# psoc6_03 register map
Vendor: Infineon Technologies; Series: PSOC6_03; File version: 1.0
CPU: CM4 r0p1, little endian, MPU, FPU, VTOR, 3 interrupt priority bits
Registers are 32-bit, read-write, reset 0x0 unless marked. A register's access mark holds for its fields unless they carry their own. Offsets are from the block's base; [hi:lo] are bit positions; {n}, {i} and the like mark numbered series; 'fields as' and 'values as' point back to an identical list.

## SRSS (part 2 of 2) — SRSS Core Registers
Base 0x40260000
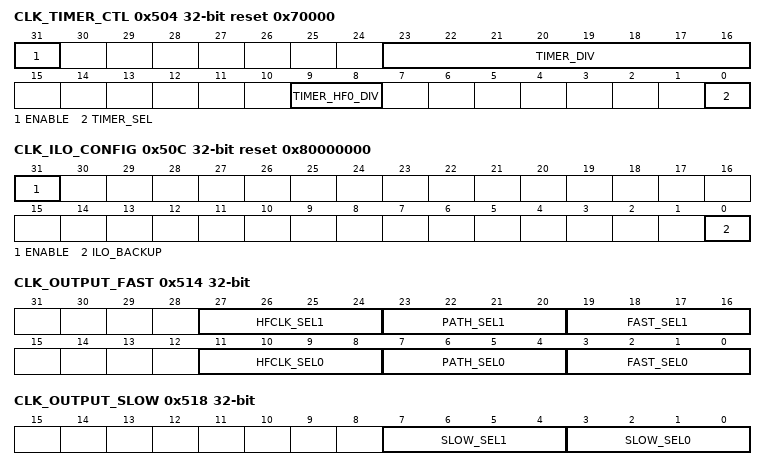
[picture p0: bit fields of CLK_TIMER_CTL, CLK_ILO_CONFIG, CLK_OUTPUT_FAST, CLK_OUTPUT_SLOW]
0x504 CLK_TIMER_CTL reset 0x70000 — Timer Clock Control Register
  [31] ENABLE — Enable for TIMERCLK. 0: TIMERCLK is off 1: TIMERCLK is enabled
  [23:16] TIMER_DIV — Divide selected timer clock source by (1+TIMER_DIV). The output of this divider is TIMERCLK Allows for integer divisions in the range [1, 256]. Do not change this setting while the timer is enabled.
  [9:8] TIMER_HF0_DIV — Predivider used when HF0_DIV is selected in TIMER_SEL. If HFCLK0 frequency is less than 100MHz and has approximately 50 percent duty cycle, then no division is required (NO_DIV). Otherwise, select a divide ratio of 2, 4, or 8 before selected HF0_DIV as the timer clock.
    0=NO_DIV (Transparent mode, feed through selected clock source w/o dividing or correcting duty cycle.); 1=DIV_BY_2 (Divide HFCLK0 by 2.); 2=DIV_BY_4 (Divide HFCLK0 by 4.); 3=DIV_BY_8 (Divide HFCLK0 by 8.)
  [0] TIMER_SEL — Select source for TIMERCLK. The output of this mux can be further divided using TIMER_DIV.
    0=IMO (IMO - Internal Main Oscillator); 1=HF0_DIV (Select the output of the predivider configured by TIMER_HF0_DIV.)
0x50C CLK_ILO_CONFIG reset 0x80000000 — ILO Configuration
  [31] ENABLE — Master enable for ILO. Writes to this field are ignored unless the WDT is unlocked using WDT_LOCK register. After enabling, it takes at most two cycles to reach the accuracy spec.
  [0] ILO_BACKUP — If backup domain is present on this product, this register indicates that ILO should stay enabled for use by backup domain during XRES, HIBERNATE mode, and through power-related resets like BOD on VDDD/VCCD. Writes to this field are ignored unless the WDT is unlocked using WDT_LOCK register. 0: ILO turns off at XRES/BOD event or HIBERNATE entry. 1: ILO remains on if backup domain is present and powered even for XRES/BOD or HIBERNATE entry.
0x510 CLK_IMO_CONFIG reset 0x80000000 — IMO Configuration
  [31] ENABLE — Master enable for IMO oscillator. This bit must be high at all times for all functions to work properly. Hardware will automatically disable the IMO during HIBERNATE and XRES. It will automatically disable during DEEPSLEEP if CLK_MFO_CONFIG.DPSLP_ENABLE==0.
0x514 CLK_OUTPUT_FAST — Fast Clock Output Select Register
  [27:24] HFCLK_SEL1 — Selects a HFCLK tree for use in fast clock output #1 logic
  [23:20] PATH_SEL1 — Selects a clock path to use in fast clock output #1 logic. 0: FLL output 1-15: PLL output on path1-path15 (if available)
  [19:16] FAST_SEL1 — Select signal for fast clock output #1
    0=NC (Disabled - output is 0. For power savings, clocks are blocked before entering any muxes, including PATH_SEL1 and HFCLK_SEL1.); 1=ECO (External Crystal Oscillator (ECO)); 2=EXTCLK (External clock input (EXTCLK)); 3=ALTHF (Alternate High-Frequency (ALTHF) clock input to SRSS); 4=TIMERCLK (Timer clock. It is grouped with the fast clocks because it may be a gated version of a fast clock, and therefore may have a short high pulse.); 5=PATH_SEL1 (Selects the clock path chosen by PATH_SEL1 field); 6=HFCLK_SEL1 (Selects the output of the HFCLK_SEL1 mux); 7=SLOW_SEL1 (Selects the output of CLK_OUTPUT_SLOW.SLOW_SEL1)
  [11:8] HFCLK_SEL0 — Selects a HFCLK tree for use in fast clock output #0
  [7:4] PATH_SEL0 — Selects a clock path to use in fast clock output #0 logic. 0: FLL output 1-15: PLL output on path1-path15 (if available)
  [3:0] FAST_SEL0 — Select signal for fast clock output #0
    0=NC (Disabled - output is 0. For power savings, clocks are blocked before entering any muxes, including PATH_SEL0 and HFCLK_SEL0.); 1=ECO (External Crystal Oscillator (ECO)); 2=EXTCLK (External clock input (EXTCLK)); 3=ALTHF (Alternate High-Frequency (ALTHF) clock input to SRSS); 4=TIMERCLK (Timer clock. It is grouped with the fast clocks because it may be a gated version of a fast clock, and therefore may have a short high pulse.); 5=PATH_SEL0 (Selects the clock path chosen by PATH_SEL0 field); 6=HFCLK_SEL0 (Selects the output of the HFCLK_SEL0 mux); 7=SLOW_SEL0 (Selects the output of CLK_OUTPUT_SLOW.SLOW_SEL0)
0x518 CLK_OUTPUT_SLOW — Slow Clock Output Select Register
  [7:4] SLOW_SEL1 — Select signal for slow clock output #1
    0=NC (Disabled - output is 0. For power savings, clocks are blocked before entering any muxes.); 1=ILO (Internal Low Speed Oscillator (ILO)); 2=WCO (Watch-Crystal Oscillator (WCO)); 3=BAK (Root of the Backup domain clock tree (BAK)); 4=ALTLF (Alternate low-frequency clock input to SRSS (ALTLF)); 5=LFCLK (Root of the low-speed clock tree (LFCLK)); 6=IMO (Internal Main Oscillator (IMO). This is grouped with the slow clocks so it can be observed during DEEPSLEEP entry/exit.); 7=SLPCTRL (Sleep Controller clock (SLPCTRL). This is grouped with the slow clocks so it can be observed during DEEPSLEEP entry/exit.); 8=PILO (Precision Internal Low Speed Oscillator (PILO))
  [3:0] SLOW_SEL0 — Select signal for slow clock output #0
    values as SLOW_SEL1
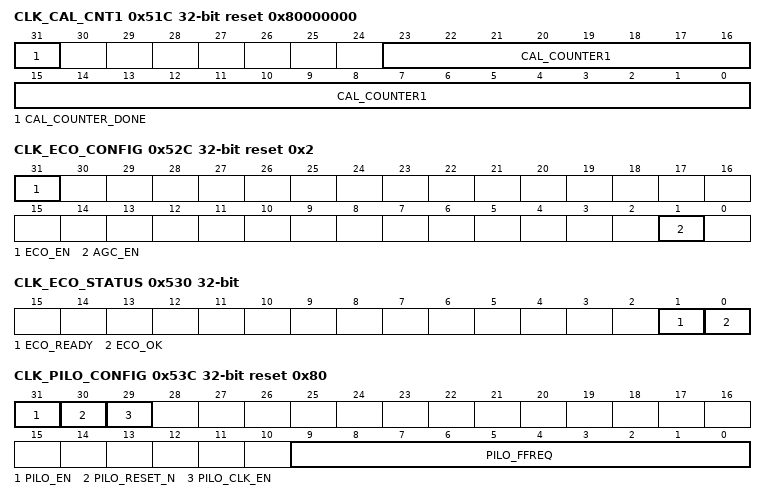
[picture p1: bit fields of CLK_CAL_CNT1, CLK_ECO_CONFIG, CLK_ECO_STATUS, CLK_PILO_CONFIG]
0x51C CLK_CAL_CNT1 reset 0x80000000 — Clock Calibration Counter 1
  [31] CAL_COUNTER_DONE ro — Status bit indicating that the internal counter #1 is finished counting and CLK_CAL_CNT2.COUNTER stopped counting up
  [23:0] CAL_COUNTER1 — Down-counter clocked on fast clock output #0 (see CLK_OUTPUT_FAST). This register always reads as zero. Counting starts internally when this register is written with a nonzero value. CAL_COUNTER_DONE goes immediately low to indicate that the counter has started and will be asserted when the counters are done. Do not write this field unless CAL_COUNTER_DONE==1. Both clocks must be running or the measurement will not complete. A stalled counter can be recovered by selecting valid clocks, waiting until the measurement completes, and discarding the first result.
0x520 CLK_CAL_CNT2 ro — Clock Calibration Counter 2
  [23:0] CAL_COUNTER2 — Up-counter clocked on fast clock output #1 (see CLK_OUTPUT_FAST). When CLK_CAL_CNT1.CAL_COUNTER_DONE==1, the counter is stopped and can be read by SW. Do not read this value unless CAL_COUNTER_DONE==1. The expected final value is related to the ratio of clock frequencies used for the two counters and the value loaded into counter 1: CLK_CAL_CNT2.COUNTER=(F_cnt2/F_cnt1)*(CLK_CAL_CNT1.COUNTER)
0x52C CLK_ECO_CONFIG reset 0x2 — ECO Configuration Register
  [31] ECO_EN — Master enable for ECO oscillator.
  [1] AGC_EN — Automatic Gain Control (AGC) enable. When set, the oscillation amplitude is controlled to the level selected by ECO_TRIM0.ATRIM. When low, the amplitude is not explicitly controlled and can be as high as the vddd supply. WARNING: use care when disabling AGC because driving a crystal beyond its rated limit can permanently damage the crystal.
0x530 CLK_ECO_STATUS ro — ECO Status Register
  [1] ECO_READY — Indicates the ECO internal oscillator circuit has had enough time to fully stabilize. This is the output of a counter since ECO was enabled, and it does not check the ECO output. It is recommended to also confirm ECO_OK==1.
  [0] ECO_OK — Indicates the ECO internal oscillator circuit has sufficient amplitude. It may not meet the PPM accuracy or duty cycle spec.
0x53C CLK_PILO_CONFIG reset 0x80 — Precision ILO Configuration Register
  [31] PILO_EN — Enable PILO. When enabling PILO, set PILO_EN=1, wait 1ms, then PILO_RESET_N=1 and PILO_CLK_EN=1. When disabling PILO, clear PILO_EN=0, PILO_RESET_N=0, and PLO_CLK_EN=0 in the same write cycle.
  [30] PILO_RESET_N — Reset the PILO. See PILO_EN field for required sequencing.
  [29] PILO_CLK_EN — Enable the PILO clock output. See PILO_EN field for required sequencing.
  [9:0] PILO_FFREQ — Fine frequency trim allowing +/-250ppm accuracy with periodic calibration. The nominal step size of the LSB is 8Hz.
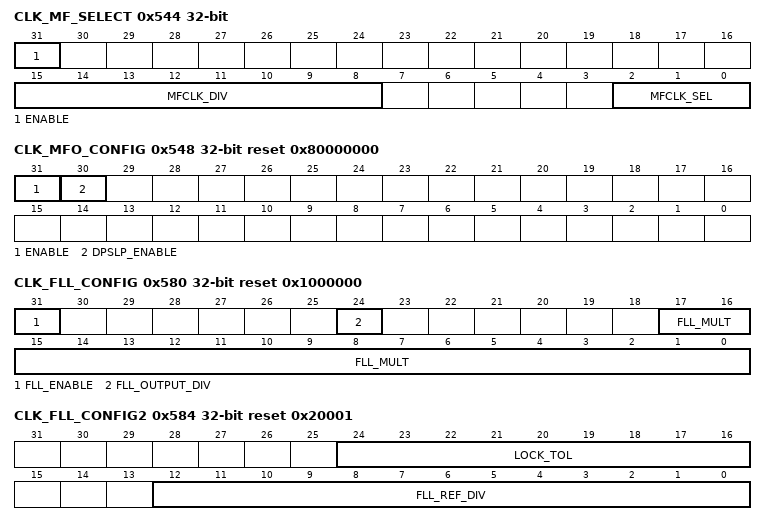
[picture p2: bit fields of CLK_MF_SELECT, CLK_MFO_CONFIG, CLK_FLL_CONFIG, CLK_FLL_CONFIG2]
0x544 CLK_MF_SELECT — Medium Frequency Clock Select Register
  [31] ENABLE — Enable for MFCLK (clk_mf).
  [15:8] MFCLK_DIV — Divide selected clock source by (1+MFCLK_DIV). The output of this divider is MFCLK (clk_mf). Allows for integer divisions in the range [1, 256]. Do not change this setting while ENABLE==1.
  [2:0] MFCLK_SEL — Select source for MFCLK (clk_mf). Note that not all products support all clock sources. Selecting a clock source that is not supported results in undefined behavior.
    0=MFO (MFO - medium frequency oscillator)
0x548 CLK_MFO_CONFIG reset 0x80000000 — MFO Configuration Register
  [31] ENABLE — Enable for MFO.
  [30] DPSLP_ENABLE — Enable for MFO during DEEPSLEEP. This bit is ignored when ENABLE==0. When ENABLE==1: 0: MFO is automatically disabled during DEEPSLEEP and enables upon wakeup; 1: MFO is kept enabled throughout DEEPSLEEP
0x580 CLK_FLL_CONFIG reset 0x1000000 — FLL Configuration Register
  [31] FLL_ENABLE — Master enable for FLL. The FLL requires firmware sequencing when enabling, disabling, and entering/exiting DEEPSLEEP. To enable the FLL, first enable the CCO by writing CLK_FLL_CONFIG4.CCO_ENABLE=1 and wait until CLK_FLL_STATUS.CCO_READY==1. Next, ensure the reference clock has stabilized and CLK_FLL_CONFIG3.BYPASS_SEL=FLL_REF. Next, write FLL_ENABLE=1 and wait until CLK_FLL_STATUS.LOCKED==1. Finally, write CLK_FLL_CONFIG3.BYPASS_SEL=FLL_OUT to switch to the FLL output. It takes seven reference clock cycles plus four FLL output cycles to switch to the FLL output. Do not disable the FLL before this time completes. To disable the FLL, write CLK_FLL_CONFIG3.BYPASS_SEL=FLL_REF and (optionally) read the same register to ensure the write completes. Then, wait at least seven FLL reference clock cycles before disabling it with FLL_ENABLE=0. Lastly, disable the CCO by writing CLK_FLL_CONFIG4.CCO_ENABLE=0. Before entering DEEPSLEEP, either disable the FLL using above sequence or use the following procedure to deselect/select it before/after DEEPSLEEP. Before entering DEEPSLEEP, write CLK_FLL_CONFIG3.BYPASS_SEL=FLL_REF to change the FLL to use its reference clock. After DEEPSLEEP wakeup, wait until CLK_FLL_STATUS.LOCKED==1 and then write CLK_FLL_CONFIG3.BYPASS_SEL=FLL_OUT to switch to the FLL output. 0: Block is powered off 1: Block is powered on
  [24] FLL_OUTPUT_DIV — Control bits for Output divider. Set the divide value before enabling the FLL, and do not change it while FLL is enabled. 0: no division 1: divide by 2
  [17:0] FLL_MULT — Multiplier to determine CCO frequency in multiples of the frequency of the selected reference clock (Fref). Ffll = (FLL_MULT) * (Fref / REFERENCE_DIV) / (OUTPUT_DIV+1)
0x584 CLK_FLL_CONFIG2 reset 0x20001 — FLL Configuration Register 2
  [24:16] LOCK_TOL — Lock tolerance sets the error threshold for when the FLL output is considered locked to the reference input. A high tolerance can be used to lock more quickly or to track a less accurate source. The tolerance should be set so that the FLL does not unlock under normal conditions. The tolerance is the allowed difference between the count value for the ideal formula and the measured value. 0: tolerate error of 1 count value 1: tolerate error of 2 count values ... 511: tolerate error of 512 count values
  [12:0] FLL_REF_DIV — Control bits for reference divider. Set the divide value before enabling the FLL, and do not change it while FLL is enabled. 0: illegal (undefined behavior) 1: divide by 1 ... 8191: divide by 8191
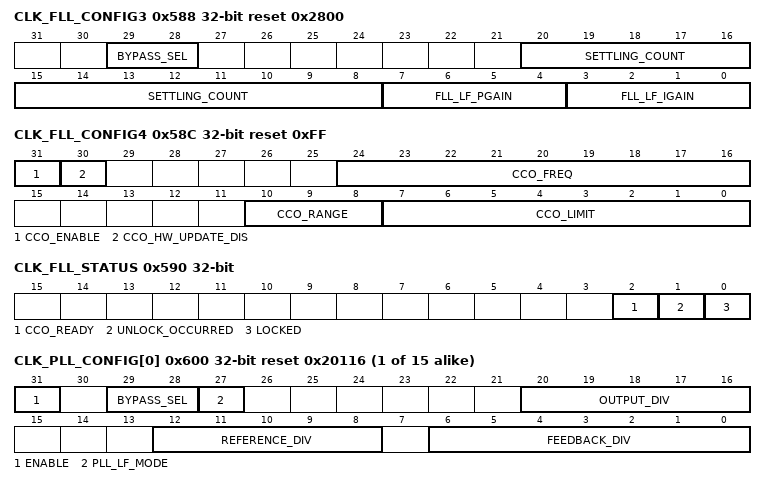
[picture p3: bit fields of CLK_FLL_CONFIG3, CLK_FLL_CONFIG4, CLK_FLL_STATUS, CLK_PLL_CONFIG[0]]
0x588 CLK_FLL_CONFIG3 reset 0x2800 — FLL Configuration Register 3
  [29:28] BYPASS_SEL — Bypass mux located just after FLL output. See FLL_ENABLE description for instructions on how to use this field when enabling/disabling the FLL.
    0=AUTO (N/A); 1=AUTO1 (N/A); 2=FLL_REF (Select FLL reference input (bypass mode). Ignores lock indicator); 3=FLL_OUT (Select FLL output. Ignores lock indicator.)
  [20:8] SETTLING_COUNT — Number of undivided reference clock cycles to wait after changing the CCO trim until the loop measurement restarts. A delay allows the CCO output to settle and gives a more accurate measurement. The default is tuned to an 8MHz reference clock since the IMO is expected to be the most common use case. 0: no settling time 1: wait one reference clock cycle ... 8191: wait 8191 reference clock cycles
  [7:4] FLL_LF_PGAIN — FLL Loop Filter Gain Setting #2. The proportional gain is the sum of FLL_LF_IGAIN and FLL_LF_PGAIN. 0: 1/256 1: 1/128 2: 1/64 3: 1/32 4: 1/16 5: 1/8 6: 1/4 7: 1/2 8: 1.0 9: 2.0 10: 4.0 11: 8.0 >=12: illegal
  [3:0] FLL_LF_IGAIN — FLL Loop Filter Gain Setting #1. The proportional gain is the sum of FLL_LF_IGAIN and FLL_LF_PGAIN. 0: 1/256 1: 1/128 2: 1/64 3: 1/32 4: 1/16 5: 1/8 6: 1/4 7: 1/2 8: 1.0 9: 2.0 10: 4.0 11: 8.0 >=12: illegal
0x58C CLK_FLL_CONFIG4 reset 0xFF — FLL Configuration Register 4
  [31] CCO_ENABLE — Enable the CCO. It is required to enable the CCO before using the FLL. 0: Block is powered off 1: Block is powered on
  [30] CCO_HW_UPDATE_DIS — Disable CCO frequency update by FLL hardware 0: Hardware update of CCO settings is allowed. Use this setting for normal FLL operation. 1: Hardware update of CCO settings is disabled. Use this setting for open-loop FLL operation.
  [24:16] CCO_FREQ — CCO frequency code. This is updated by HW when the FLL is enabled. It can be manually updated to use the CCO in an open loop configuration. The meaning of each frequency code depends on the range.
  [10:8] CCO_RANGE — Frequency range of CCO
    0=RANGE0 (Target frequency is in range [48, 64) MHz); 1=RANGE1 (Target frequency is in range [64, 85) MHz); 2=RANGE2 (Target frequency is in range [85, 113) MHz); 3=RANGE3 (Target frequency is in range [113, 150) MHz); 4=RANGE4 (Target frequency is in range [150, 200] MHz)
  [7:0] CCO_LIMIT — Maximum CCO offset allowed (used to prevent FLL dynamics from selecting an CCO frequency that the logic cannot support)
0x590 CLK_FLL_STATUS — FLL Status Register
  [2] CCO_READY ro — This indicates that the CCO is internally settled and ready to use.
  [1] UNLOCK_OCCURRED
  [0] LOCKED ro — FLL Lock Indicator. LOCKED is high when FLL is within CLK_FLL_CONFIG2.LOCK_TOL. If FLL is outside LOCK_TOL, LOCKED goes low. Note that this can happen during normal operation, if FLL needs to recalculate due to a change in the reference clock, change in voltage, or change in temperature.
{0x600+4i} CLK_PLL_CONFIG[{i}] (i=0..14) reset 0x20116 — PLL Configuration Register
  [31] ENABLE — Master enable for PLL. Setup FEEDBACK_DIV, REFERENCE_DIV, and OUTPUT_DIV at least one cycle before setting ENABLE=1. To disable the PLL, first deselect it using .BYPASS_SEL=PLL_REF, wait at least six PLL clock cycles, and then disable it with .ENABLE=0. Fpll = (FEEDBACK_DIV) * (Fref / REFERENCE_DIV) / (OUTPUT_DIV) 0: Block is disabled 1: Block is enabled
  [29:28] BYPASS_SEL — Bypass mux located just after PLL output. This selection is glitch-free and can be changed while the PLL is running.
    0=AUTO (Automatic using lock indicator. When unlocked, automatically selects PLL reference input (bypass mode). When locked, automatically selects PLL output.); 1=AUTO1 (Same as AUTO); 2=PLL_REF (Select PLL reference input (bypass mode). Ignores lock indicator); 3=PLL_OUT (Select PLL output. Ignores lock indicator.)
  [27] PLL_LF_MODE — VCO frequency range selection. Configure this bit according to the targeted VCO frequency. Do not change this setting while the PLL is enabled. 0: VCO frequency is [200MHz, 400MHz] 1: VCO frequency is [170MHz, 200MHz)
  [20:16] OUTPUT_DIV — Control bits for Output divider. Set the divide value before enabling the PLL, and do not change it while PLL is enabled. 0: illegal (undefined behavior) 1: illegal (undefined behavior) 2: divide by 2. Suitable for direct usage as HFCLK source. ... 16: divide by 16. Suitable for direct usage as HFCLK source. >16: illegal (undefined behavior)
  [12:8] REFERENCE_DIV — Control bits for reference divider. Set the divide value before enabling the PLL, and do not change it while PLL is enabled. 0: illegal (undefined behavior) 1: divide by 1 ... 20: divide by 20 others: illegal (undefined behavior)
  [6:0] FEEDBACK_DIV — Control bits for feedback divider. Set the divide value before enabling the PLL, and do not change it while PLL is enabled. 0-21: illegal (undefined behavior) 22: divide by 22 ... 112: divide by 112 >112: illegal (undefined behavior)
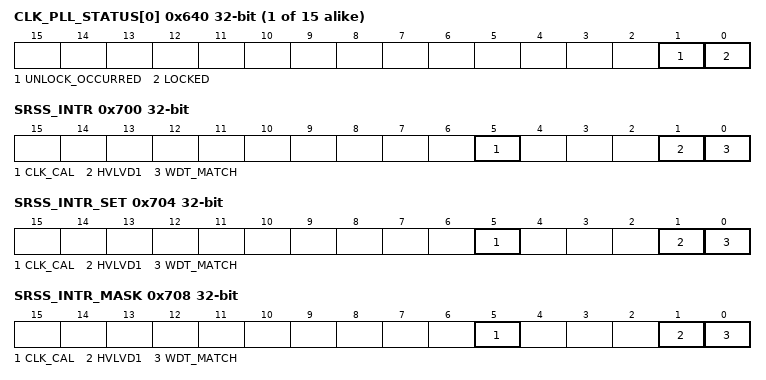
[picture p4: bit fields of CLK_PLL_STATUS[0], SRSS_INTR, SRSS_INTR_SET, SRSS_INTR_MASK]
{0x640+4i} CLK_PLL_STATUS[{i}] (i=0..14) — PLL Status Register
  [1] UNLOCK_OCCURRED — This bit sets whenever the PLL Lock bit goes low, and stays set until cleared by firmware.
  [0] LOCKED ro — PLL Lock Indicator
0x700 SRSS_INTR — SRSS Interrupt Register
  [5] CLK_CAL — Clock calibration counter is done. This field is reset during DEEPSLEEP mode.
  [1] HVLVD1 — Interrupt for low voltage detector HVLVD1
  [0] WDT_MATCH — WDT Interrupt Request. This bit is set each time WDT_COUNTR==WDT_MATCH. W1C also feeds the watch dog. Missing 2 interrupts in a row will generate a reset. Due to internal synchronization, it takes 2 SYSCLK cycles to update after a W1C.
0x704 SRSS_INTR_SET — SRSS Interrupt Set Register
  [5] CLK_CAL — Set interrupt for clock calibration counter done. This field is reset during DEEPSLEEP mode.
  [1] HVLVD1 — Set interrupt for low voltage detector HVLVD1
  [0] WDT_MATCH — Set interrupt for low voltage detector WDT_MATCH
0x708 SRSS_INTR_MASK — SRSS Interrupt Mask Register
  [5] CLK_CAL — Mask for clock calibration done
  [1] HVLVD1 — Mask for low voltage detector HVLVD1
  [0] WDT_MATCH — Mask for watchdog timer. Clearing this bit will not forward the interrupt to the CPU. It will not, however, disable the WDT reset generation on 2 missed interrupts. When WDT resets the chip, it also internally pends an interrupt that survives the reset. To prevent unintended ISR execution, clear SRSS_INTR.WDT_MATCH before setting this bit.
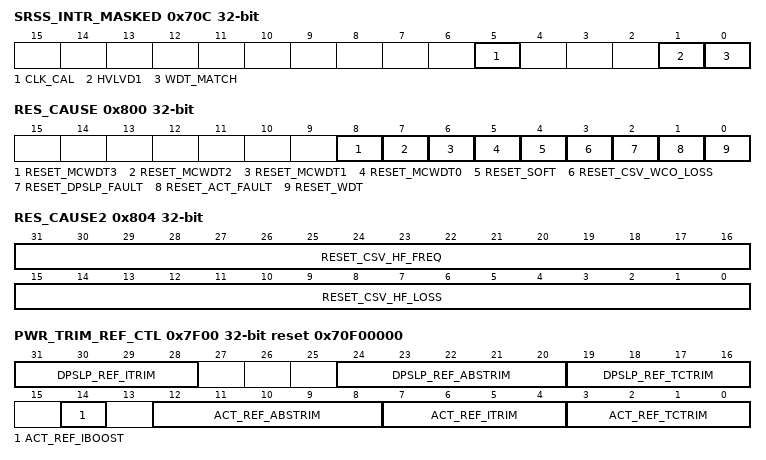
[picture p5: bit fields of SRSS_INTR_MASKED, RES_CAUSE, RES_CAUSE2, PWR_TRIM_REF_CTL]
0x70C SRSS_INTR_MASKED ro — SRSS Interrupt Masked Register
  [5] CLK_CAL — Logical and of corresponding request and mask bits.
  [1] HVLVD1 — Logical and of corresponding request and mask bits.
  [0] WDT_MATCH — Logical and of corresponding request and mask bits.
0x710 SRSS_INTR_CFG — SRSS Interrupt Configuration Register
  [1:0] HVLVD1_EDGE_SEL — Sets which edge(s) will trigger an IRQ for HVLVD1
    0=DISABLE (Disabled); 1=RISING (Rising edge); 2=FALLING (Falling edge); 3=BOTH (Both rising and falling edges)
0x800 RES_CAUSE — Reset Cause Observation Register
  [8] RESET_MCWDT3 — Multi-Counter Watchdog timer reset #3 has occurred since last power cycle. This hardware is not present in PSoC6 devices.
  [7] RESET_MCWDT2 — Multi-Counter Watchdog timer reset #2 has occurred since last power cycle. This hardware is not present in PSoC6 devices.
  [6] RESET_MCWDT1
  [5] RESET_MCWDT0
  [4] RESET_SOFT
  [3] RESET_CSV_WCO_LOSS
  [2] RESET_DPSLP_FAULT
  [1] RESET_ACT_FAULT
  [0] RESET_WDT
0x804 RES_CAUSE2 — Reset Cause Observation Register 2
  [31:16] RESET_CSV_HF_FREQ — Clock supervision logic requested a reset due to frequency error of high-frequency clock. Each bit index K corresponds to a HFCLK<K>. Unimplemented clock bits return zero.
  [15:0] RESET_CSV_HF_LOSS — Clock supervision logic requested a reset due to loss of a high-frequency clock. Each bit index K corresponds to a HFCLK<K>. Unimplemented clock bits return zero.
0x7F00 PWR_TRIM_REF_CTL reset 0x70F00000 — Reference Trim Register
  [31:28] DPSLP_REF_ITRIM — DeepSleep current reference trim. This register is only reset by XRES/POR/BOD/HIBERNATE.
  [24:20] DPSLP_REF_ABSTRIM — DeepSleep-Reference absolute voltage trim. This register is only reset by XRES/POR/BOD/HIBERNATE.
  [19:16] DPSLP_REF_TCTRIM — DeepSleep-Reference temperature trim. This register is only reset by XRES/POR/BOD/HIBERNATE. 0 -> default setting at POR; not for trimming use others -> normal trim range
  [14] ACT_REF_IBOOST — Active-Reference current boost. This register is only reset by XRES/POR/BOD/HIBERNATE. 0: normal operation others: risk mitigation
  [12:8] ACT_REF_ABSTRIM — Active-Reference absolute voltage trim. This register is only reset by XRES/POR/BOD/HIBERNATE. 0 -> default setting at POR; not for trimming use others -> normal trim range
  [7:4] ACT_REF_ITRIM — Active-Reference current trim. This register is only reset by XRES/POR/BOD/HIBERNATE. 0 -> default setting at POR; not for trimming use others -> normal trim range
  [3:0] ACT_REF_TCTRIM — Active-Reference temperature trim. This register is only reset by XRES/POR/BOD/HIBERNATE. 0 -> default setting at POR; not for trimming use others -> normal trim range
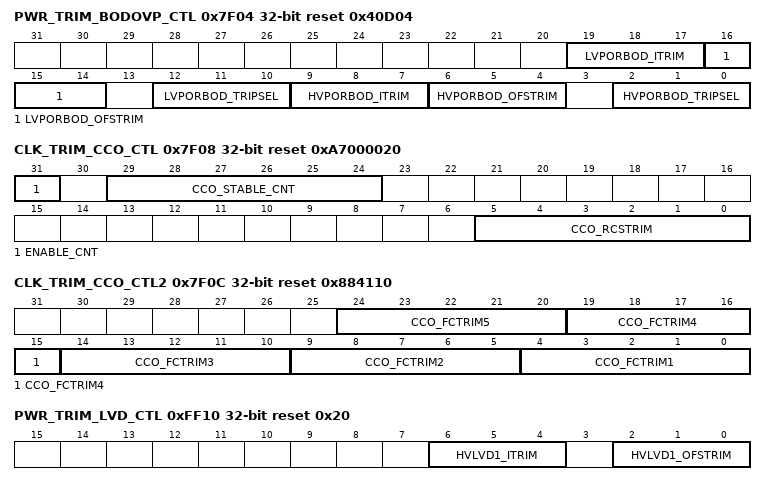
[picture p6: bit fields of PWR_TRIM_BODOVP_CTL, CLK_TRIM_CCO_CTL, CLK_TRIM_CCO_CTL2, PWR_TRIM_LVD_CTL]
0x7F04 PWR_TRIM_BODOVP_CTL reset 0x40D04 — BOD/OVP Trim Register
  [19:17] LVPORBOD_ITRIM — LVPORBOD current trim. This register is only reset by XRES/POR/BOD/HIBERNATE.
  [16:14] LVPORBOD_OFSTRIM — LVPORBOD offset trim. This register is only reset by XRES/POR/BOD/HIBERNATE.
  [12:10] LVPORBOD_TRIPSEL — LVPORBOD trip point selection. Monitors vccd. This register is only reset by XRES/POR/BOD/HIBERNATE.
  [9:7] HVPORBOD_ITRIM — HVPORBOD current trim. This register is only reset by XRES/POR/BOD/HIBERNATE.
  [6:4] HVPORBOD_OFSTRIM — HVPORBOD offset trim. This register is only reset by XRES/POR/BOD/HIBERNATE.
  [2:0] HVPORBOD_TRIPSEL — HVPORBOD trip point selection. Monitors vddd. This register is only reset by XRES/POR/BOD/HIBERNATE.
0x7F08 CLK_TRIM_CCO_CTL reset 0xA7000020 — CCO Trim Register
  [31] ENABLE_CNT — Enables the automatic stabilization counter.
  [29:24] CCO_STABLE_CNT — Terminal count for the stabilization counter from CCO_ENABLE until stable.
  [5:0] CCO_RCSTRIM — CCO reference current source trim.
0x7F0C CLK_TRIM_CCO_CTL2 reset 0x884110 — CCO Trim Register 2
  [24:20] CCO_FCTRIM5 — CCO frequency 5th range calibration
  [19:15] CCO_FCTRIM4 — CCO frequency 4th range calibration
  [14:10] CCO_FCTRIM3 — CCO frequency 3rd range calibration
  [9:5] CCO_FCTRIM2 — CCO frequency 2nd range calibration
  [4:0] CCO_FCTRIM1 — CCO frequency 1st range calibration
0x7F30 PWR_TRIM_WAKE_CTL — Wakeup Trim Register
  [7:0] WAKE_DELAY — Wakeup holdoff. Spec (fastest) wake time is achieved with a setting of 0. Additional delay can be added for debugging or workaround. The delay is counted by the IMO.
0xFF10 PWR_TRIM_LVD_CTL reset 0x20 — LVD Trim Register
  [6:4] HVLVD1_ITRIM — HVLVD1 current trim
  [2:0] HVLVD1_OFSTRIM — HVLVD1 offset trim
0xFF18 CLK_TRIM_ILO_CTL reset 0x2C — ILO Trim Register
  [5:0] ILO_FTRIM — ILO frequency trims. LSB step size is 1.5 percent (typical) of the frequency.
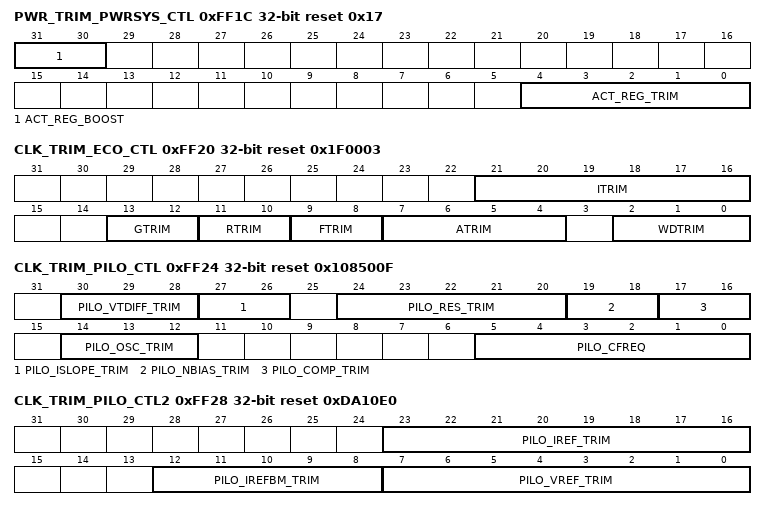
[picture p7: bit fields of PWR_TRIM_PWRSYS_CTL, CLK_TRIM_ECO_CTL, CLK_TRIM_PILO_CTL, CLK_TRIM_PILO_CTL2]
0xFF1C PWR_TRIM_PWRSYS_CTL reset 0x17 (reset mask 0x1F) — Power System Trim Register
  [31:30] ACT_REG_BOOST — Controls the tradeoff between output current and internal operating current for the Active Regulator. The maximum output current depends on the silicon implementation, but an application may limit its maximum current to less than that. This may allow a reduction in the internal operating current of the regulator. The regulator internal operating current depends on the boost setting: 2'b00: 50uA 2'b01: 100uA 2'b10: 150uA 2'b11: 200uA The allowed setting is a lookup table based on the chip-specific maximum (set in factory) and an application-specific maximum (set by customer). The defaults are set assuming the application consumes the maximum allowed by the chip. 50mA chip: 2'b00 (default); 100mA chip: 2'b00 (default); 150mA chip: 50..100mA app => 2'b00, 150mA app => 2'b01 (default); 200mA chip: 50mA app => 2'b00, 100..150mA app => 2'b01, 200mA app => 2'b10 (default); 250mA chip: 50mA app => 2'b00, 100..150mA app => 2'b01, 200..250mA app => 2'b10 (default); 300mA chip: 50mA app => 2'b00, 100..150mA app => 2'b01, 200..250mA app => 2'b10, 300mA app => 2'b11 (default); This register is only reset by XRES/POR/BOD/HIBERNATE.
  [4:0] ACT_REG_TRIM — Trim for the Active-Regulator. This sets the output voltage level. This register is only reset by XRES/POR/BOD/HIBERNATE. The nominal output voltage is vccd=812.5mV + ACT_REG_TRIM*12.5mV. The actual output voltage will vary depending on conditions and load. The following settings are explicitly shown for convenience, and other values may be calculated using the formula: 5'h07: 900mV (nominal) 5'h17: 1100mV (nominal)
0xFF20 CLK_TRIM_ECO_CTL reset 0x1F0003 — ECO Trim Register
  [21:16] ITRIM — Current Trim
  [13:12] GTRIM — Gain Trim - Startup time
  [11:10] RTRIM — Feedback resistor Trim
  [9:8] FTRIM — Filter Trim - 3rd harmonic oscillation
  [7:4] ATRIM — Amplitude trim to set the crystal drive level when ECO_CONFIG.AGC_EN=1. WARNING: use care when setting this field because driving a crystal beyond its rated limit can permanently damage the crystal. 0x0 - 150mV 0x1 - 175mV 0x2 - 200mV 0x3 - 225mV 0x4 - 250mV 0x5 - 275mV 0x6 - 300mV 0x7 - 325mV 0x8 - 350mV 0x9 - 375mV 0xA - 400mV 0xB - 425mV 0xC - 450mV 0xD - 475mV 0xE - 500mV 0xF - 525mV
  [2:0] WDTRIM — Watch Dog Trim - Delta voltage below steady state level 0x0 - 50mV 0x1 - 75mV 0x2 - 100mV 0x3 - 125mV 0x4 - 150mV 0x5 - 175mV 0x6 - 200mV 0x7 - 225mV
0xFF24 CLK_TRIM_PILO_CTL reset 0x108500F — PILO Trim Register
  [30:28] PILO_VTDIFF_TRIM — Trim for VT-DIFF output (internal power supply)
  [27:26] PILO_ISLOPE_TRIM — Trim for beta-multiplier current slope
  [24:20] PILO_RES_TRIM — Trim for beta-multiplier branch current
  [19:18] PILO_NBIAS_TRIM — Trim for biasn by trimming sub-Vth NMOS width in beta-multiplier
  [17:16] PILO_COMP_TRIM — Trim for comparator bias current.
  [14:12] PILO_OSC_TRIM — Trim for current in oscillator block.
  [5:0] PILO_CFREQ — Coarse frequency trim to meet 32.768kHz +/-2 percent across PVT without calibration. The nominal step size of the LSB is 1kHz.
0xFF28 CLK_TRIM_PILO_CTL2 reset 0xDA10E0 — PILO Trim Register 2
  [23:16] PILO_IREF_TRIM — Trim for current reference
  [12:8] PILO_IREFBM_TRIM — Trim for beta-multiplier current reference
  [7:0] PILO_VREF_TRIM — Trim for voltage reference
0xFF2C CLK_TRIM_PILO_CTL3 reset 0x4800 — PILO Trim Register 3
  [15:0] PILO_ENGOPT — Engineering options for PILO circuits 0: Short vdda to vpwr 1: Beta:mult current change 2: Iref generation Ptat current addition 3: Disable current path in secondary Beta:mult startup circuit 4: Double oscillator current 5: Switch between deep:sub:threshold and sub:threshold stacks in Vref generation block 6: Spare 7: Ptat component increase in Iref 8: vpwr_rc and vpwr_dig_rc shorting testmode 9: Switch b/w psub connection for cascode nfet for vref generation 10: Switch between sub:threshold and deep:sub:threshold stacks in comparator. 15-11: Frequency fine trim. See AKK-444 for an overview of the trim strategy.
